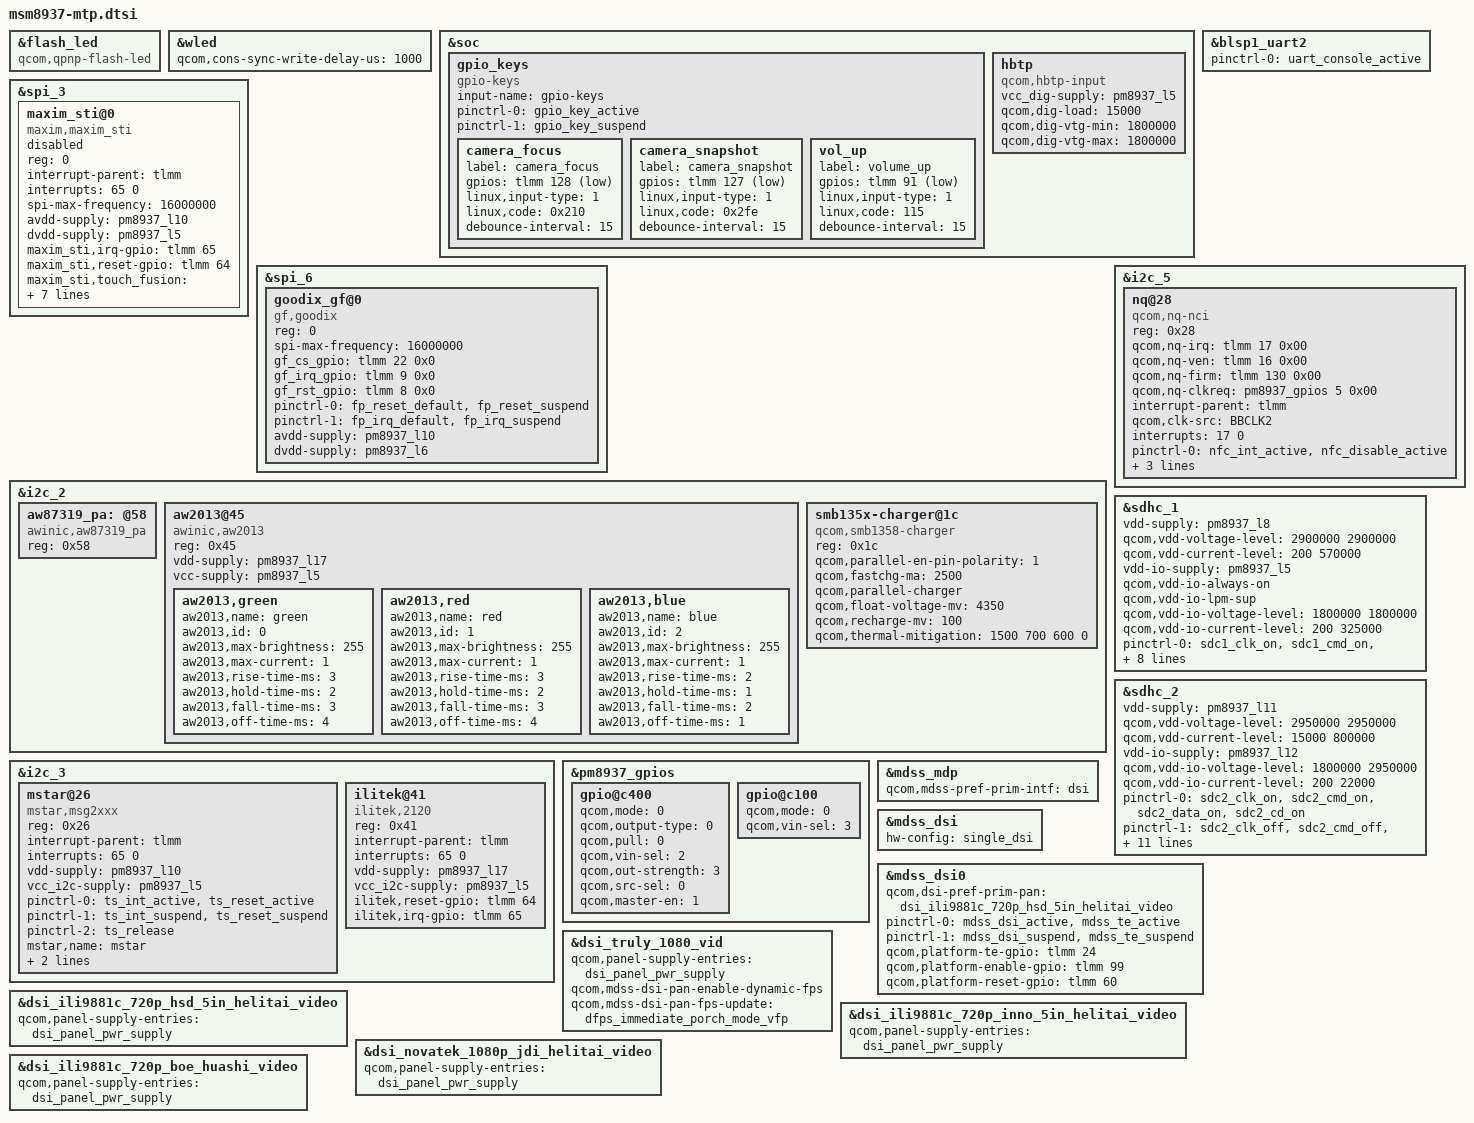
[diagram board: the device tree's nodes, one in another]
/*
 * Copyright (c) 2015-2016, The Linux Foundation. All rights reserved.
 *
 * This program is free software; you can redistribute it and/or modify
 * it under the terms of the GNU General Public License version 2 and
 * only version 2 as published by the Free Software Foundation.
 *
 * This program is distributed in the hope that it will be useful,
 * but WITHOUT ANY WARRANTY; without even the implied warranty of
 * MERCHANTABILITY or FITNESS FOR A PARTICULAR PURPOSE.  See the
 * GNU General Public License for more details.
 */

#include "msm8937-pinctrl.dtsi"
#include "msm8937-camera-sensor-mtp.dtsi"

&flash_led {
	compatible = "qcom,qpnp-flash-led";
};

&wled {
	qcom,cons-sync-write-delay-us = <1000>;
};

&soc {
	gpio_keys {
		compatible = "gpio-keys";
		input-name = "gpio-keys";
		pinctrl-names = "tlmm_gpio_key_active","tlmm_gpio_key_suspend";
		pinctrl-0 = <&gpio_key_active>;
		pinctrl-1 = <&gpio_key_suspend>;

		camera_focus {
			label = "camera_focus";
			gpios = <&tlmm 128 0x1>;
			linux,input-type = <1>;
			linux,code = <0x210>;
			debounce-interval = <15>;
		};

		camera_snapshot {
			label = "camera_snapshot";
			gpios = <&tlmm 127 0x1>;
			linux,input-type = <1>;
			linux,code = <0x2fe>;
			debounce-interval = <15>;
		};

		vol_up {
			label = "volume_up";
			gpios = <&tlmm 91 0x1>;
			linux,input-type = <1>;
			linux,code = <115>;
			debounce-interval = <15>;
		};
	};

	hbtp {
		compatible = "qcom,hbtp-input";
		vcc_dig-supply = <&pm8937_l5>;
		qcom,dig-load = <15000>;
		qcom,dig-vtg-min = <1800000>;
		qcom,dig-vtg-max = <1800000>;
	};
};

&blsp1_uart2 {
	status = "ok";
	pinctrl-names = "default";
	pinctrl-0 = <&uart_console_active>;
};

&spi_3 { /* BLSP1 QUP3 */
	maxim_sti@0 {
		status = "disabled";
		compatible = "maxim,maxim_sti";
		reg = <0>;
		interrupt-parent = <&tlmm>;
		interrupts = <65 0>;
		spi-max-frequency = <16000000>;
		avdd-supply = <&pm8937_l10>;
		dvdd-supply = <&pm8937_l5>;
		maxim_sti,irq-gpio = <&tlmm 65 0x00>;
		maxim_sti,reset-gpio = <&tlmm 64 0x00>;
		maxim_sti,touch_fusion = "/vendor/bin/touch_fusion";
		maxim_sti,config_file = "/etc/firmware/qtc800s.cfg";
		maxim_sti,fw_name = "qtc800s.bin";
		pinctrl-names = "pmx_ts_active","pmx_ts_suspend",
			"pmx_ts_release";
		pinctrl-0 = <&ts_int_active &ts_reset_active>;
		pinctrl-1 = <&ts_int_suspend &ts_reset_suspend>;
		pinctrl-2 = <&ts_release>;
	};
};

&spi_6 { /* BLSP2 QUP2 */
	goodix_gf@0 {
		status = "ok";
		compatible = "gf,goodix";
		reg = <0>;
		pinctrl-names = "fp_active","fp_suspend";
		spi-max-frequency = <16000000>;
		gf_cs_gpio = <&tlmm 22 0x0>;
		gf_irq_gpio = <&tlmm 9 0x0>;
		gf_rst_gpio = <&tlmm 8 0x0>;
		pinctrl-0 = <&fp_reset_default &fp_reset_suspend>;
		pinctrl-1 = <&fp_irq_default &fp_irq_suspend>;
		//interrupt-parent = <&msm_gpio>;
		//interrupts = <12 0>;
		//interrupt-names = "gf_irq";
		avdd-supply = <&pm8937_l10>;
		dvdd-supply = <&pm8937_l6>;
	};
};

&i2c_2 { /* BLSP1 QUP1 */
	aw87319_pa:@58 {
		compatible = "awinic,aw87319_pa";
		reg = <0x58>;
	};
	aw2013@45 {
		compatible = "awinic,aw2013";
		reg = <0x45>;
		vdd-supply = <&pm8937_l17>;
		vcc-supply = <&pm8937_l5>;

		aw2013,green {
			aw2013,name = "green";
			aw2013,id = <0>;
			aw2013,max-brightness = <255>;
			aw2013,max-current = <1>;
			aw2013,rise-time-ms = <3>;
			aw2013,hold-time-ms = <2>;
			aw2013,fall-time-ms = <3>;
			aw2013,off-time-ms = <4>;
		};

		aw2013,red {
			aw2013,name = "red";
			aw2013,id = <1>;
			aw2013,max-brightness = <255>;
			aw2013,max-current = <1>;
			aw2013,rise-time-ms = <3>;
			aw2013,hold-time-ms = <2>;
			aw2013,fall-time-ms = <3>;
			aw2013,off-time-ms = <4>;
		};
		aw2013,blue {
			aw2013,name = "blue";
			aw2013,id = <2>;
			aw2013,max-brightness = <255>;
			aw2013,max-current = <1>;
			aw2013,rise-time-ms = <2>;
			aw2013,hold-time-ms = <1>;
			aw2013,fall-time-ms = <2>;
			aw2013,off-time-ms = <1>;
		};
	};
	/* Parallel-charger configuration */
	smb135x-charger@1c {
		compatible = "qcom,smb1358-charger";
		reg = <0x1c>;
		qcom,parallel-en-pin-polarity = <1>;
		qcom,fastchg-ma = <2500>;
		qcom,parallel-charger;
		qcom,float-voltage-mv = <4350>;
		qcom,recharge-mv = <100>;
		qcom,thermal-mitigation = <1500 700 600 0>;
	};
};

&i2c_3 { /* BLSP2 QUP3 */
	status = "ok";
	mstar@26 {
		compatible = "mstar,msg2xxx";
		reg = <0x26>;
		interrupt-parent = <&tlmm>;
		interrupts = <65 0>;
		vdd-supply = <&pm8937_l10>;
		vcc_i2c-supply = <&pm8937_l5>;
		pinctrl-names = "pmx_ts_active","pmx_ts_suspend",
		"pmx_ts_release";
		pinctrl-0 = <&ts_int_active &ts_reset_active>;
		pinctrl-1 = <&ts_int_suspend &ts_reset_suspend>;
		pinctrl-2 = <&ts_release>;
		mstar,name ="mstar";
		mstar,rst-gpio = <&tlmm 64 0x0>;
		mstar,irq-gpio = <&tlmm 65 0x0>;

	};

	ilitek@41 {
		compatible = "ilitek,2120";
		reg = <0x41>;
		interrupt-parent = <&tlmm>;
		interrupts = <65 0>;
		vdd-supply = <&pm8937_l17>;
		vcc_i2c-supply = <&pm8937_l5>;
		ilitek,reset-gpio = <&tlmm 64 0x0>;
		ilitek,irq-gpio = <&tlmm 65 0x0>;
	};

};

&i2c_5 { /* BLSP2 QUP1 */
	nq@28 {
		compatible = "qcom,nq-nci";
		reg = <0x28>;
		qcom,nq-irq = <&tlmm 17 0x00>;
		qcom,nq-ven = <&tlmm 16 0x00>;
		qcom,nq-firm = <&tlmm 130 0x00>;
		qcom,nq-clkreq = <&pm8937_gpios 5 0x00>;
		interrupt-parent = <&tlmm>;
		qcom,clk-src = "BBCLK2";
		interrupts = <17 0>;
		interrupt-names = "nfc_irq";
		pinctrl-names = "nfc_active", "nfc_suspend";
		pinctrl-0 = <&nfc_int_active &nfc_disable_active>;
		pinctrl-1 = <&nfc_int_suspend &nfc_disable_suspend>;
		clocks = <&clock_gcc clk_bb_clk2_pin>;
		clock-names = "ref_clk";
	};
};

&sdhc_1 {
	/* device core power supply */
	vdd-supply = <&pm8937_l8>;
	qcom,vdd-voltage-level = <2900000 2900000>;
	qcom,vdd-current-level = <200 570000>;

	/* device communication power supply */
	vdd-io-supply = <&pm8937_l5>;
	qcom,vdd-io-always-on;
	qcom,vdd-io-lpm-sup;
	qcom,vdd-io-voltage-level = <1800000 1800000>;
	qcom,vdd-io-current-level = <200 325000>;

	pinctrl-names = "active", "sleep";
	pinctrl-0 = <&sdc1_clk_on &sdc1_cmd_on &sdc1_data_on &sdc1_rclk_on>;
	pinctrl-1 = <&sdc1_clk_off &sdc1_cmd_off &sdc1_data_off &sdc1_rclk_off>;

	qcom,clk-rates = <400000 20000000 25000000 50000000 100000000 192000000
								384000000>;
	qcom,nonremovable;
	qcom,bus-speed-mode = "HS400_1p8v", "HS200_1p8v", "DDR_1p8v";

	status = "ok";
};

&sdhc_2 {
	/* device core power supply */
	vdd-supply = <&pm8937_l11>;
	qcom,vdd-voltage-level = <2950000 2950000>;
	qcom,vdd-current-level = <15000 800000>;

	/* device communication power supply */
	vdd-io-supply = <&pm8937_l12>;
	qcom,vdd-io-voltage-level = <1800000 2950000>;
	qcom,vdd-io-current-level = <200 22000>;

	pinctrl-names = "active", "sleep";
	pinctrl-0 = <&sdc2_clk_on &sdc2_cmd_on &sdc2_data_on &sdc2_cd_on>;
	pinctrl-1 = <&sdc2_clk_off &sdc2_cmd_off &sdc2_data_off>;

	#address-cells = <0>;
	interrupt-parent = <&sdhc_2>;
	interrupts = <0 1 2>;
	#interrupt-cells = <1>;
	interrupt-map-mask = <0xffffffff>;
	interrupt-map = <0 &intc 0 125 0
		1 &intc 0 221 0
		2 &tlmm 67 0>;
	interrupt-names = "hc_irq", "pwr_irq", "status_irq";
	cd-gpios = <&tlmm 67 0x1>;

	qcom,clk-rates = <400000 20000000 25000000 50000000 100000000
								200000000>;
	qcom,bus-speed-mode = "SDR12", "SDR25", "SDR50", "DDR50", "SDR104";

	status = "ok";
};

&pm8937_gpios {
	gpio@c400 {
		qcom,mode = <0>;
		qcom,output-type = <0>;
		qcom,pull = <0>;
		qcom,vin-sel = <2>;
		qcom,out-strength = <3>;
		qcom,src-sel = <0>;
		qcom,master-en = <1>;
		status = "okay";
	};
};

#include "msm8937-mdss-panels.dtsi"

&mdss_mdp {
	qcom,mdss-pref-prim-intf = "dsi";
};

&mdss_dsi {
	hw-config = "single_dsi";
};

&mdss_dsi0 {
	qcom,dsi-pref-prim-pan = <&dsi_ili9881c_720p_hsd_5in_helitai_video>;
	pinctrl-names = "mdss_default", "mdss_sleep";
	pinctrl-0 = <&mdss_dsi_active &mdss_te_active>;
	pinctrl-1 = <&mdss_dsi_suspend &mdss_te_suspend>;

	qcom,platform-te-gpio = <&tlmm 24 0>;
	qcom,platform-enable-gpio = <&tlmm 99 0>;
	qcom,platform-reset-gpio = <&tlmm 60 0>;
};

&dsi_truly_1080_vid {
	qcom,panel-supply-entries = <&dsi_panel_pwr_supply>;
	qcom,mdss-dsi-pan-enable-dynamic-fps;
	qcom,mdss-dsi-pan-fps-update = "dfps_immediate_porch_mode_vfp";
};

&dsi_ili9881c_720p_hsd_5in_helitai_video {
	qcom,panel-supply-entries = <&dsi_panel_pwr_supply>;
//	qcom,mdss-dsi-pan-enable-dynamic-fps;
//	qcom,mdss-dsi-pan-fps-update = "dfps_immediate_porch_mode_vfp";
};

&dsi_ili9881c_720p_inno_5in_helitai_video {
	qcom,panel-supply-entries = <&dsi_panel_pwr_supply>;
//	qcom,mdss-dsi-pan-enable-dynamic-fps;
//	qcom,mdss-dsi-pan-fps-update = "dfps_immediate_porch_mode_vfp";
};

&dsi_novatek_1080p_jdi_helitai_video {
	qcom,panel-supply-entries = <&dsi_panel_pwr_supply>;
};

&dsi_ili9881c_720p_boe_huashi_video {
	qcom,panel-supply-entries = <&dsi_panel_pwr_supply>;
//	qcom,mdss-dsi-pan-enable-dynamic-fps;
//	qcom,mdss-dsi-pan-fps-update = "dfps_immediate_porch_mode_vfp";
};

/* PM8937 GPIO configuration */
&pm8937_gpios {
	gpio@c100 {
		qcom,mode = <0>;
		qcom,vin-sel = <3>;
		status = "okay";
	};
};
